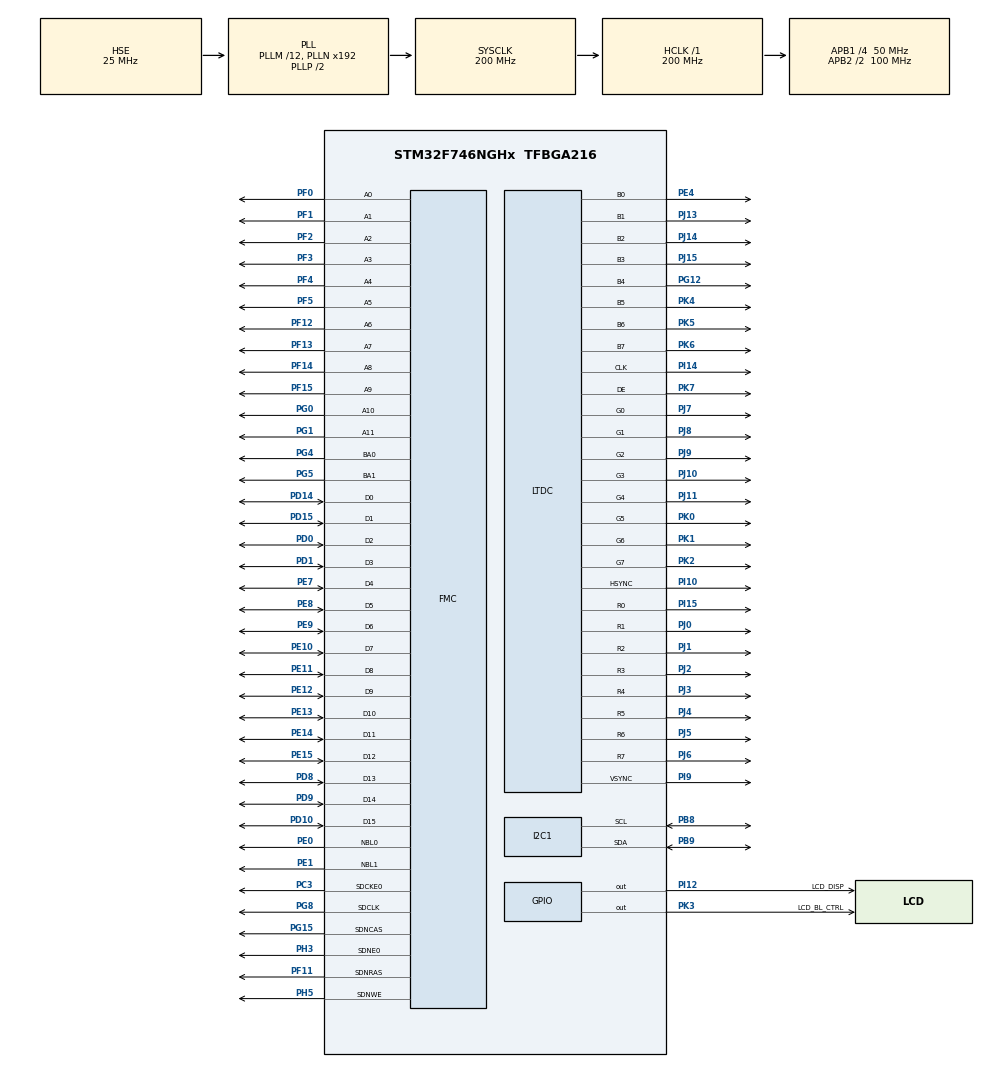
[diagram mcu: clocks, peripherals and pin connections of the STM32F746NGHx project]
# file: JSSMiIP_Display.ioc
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CORTEX_M7.CPU_DCache=Enabled
CORTEX_M7.CPU_ICache=Enabled
FMC.CASLatency1=FMC_SDRAM_CAS_LATENCY_2
FMC.ExitSelfRefreshDelay1=6
FMC.LoadToActiveDelay1=2
FMC.RCDDelay1=2
FMC.RPDelay1=2
FMC.RowCycleDelay1=6
FMC.SDClockPeriod1=FMC_SDRAM_CLOCK_PERIOD_2
FMC.SelfRefreshTime1=4
FMC.WriteRecoveryTime1=2
I2C1.Timing=0x00C0EAFF
LTDC.ActiveH=272
LTDC.ActiveW=480
LTDC.Alpha_L0=255
LTDC.Alpha_L1=255
LTDC.BlendingFactor1_L0=LTDC_BLENDING_FACTOR1_PAxCA
LTDC.BlendingFactor1_L1=LTDC_BLENDING_FACTOR1_PAxCA
LTDC.BlendingFactor2_L0=LTDC_BLENDING_FACTOR2_PAxCA
LTDC.BlendingFactor2_L1=LTDC_BLENDING_FACTOR2_PAxCA
LTDC.FBStartAdress_L0=0xC0000000
LTDC.FBStartAdress_L1=0xC0000000+0x400000
LTDC.HBP=43
LTDC.HFP=8
LTDC.HSync=1
LTDC.ImageHeight_L0=272
LTDC.ImageHeight_L1=272
LTDC.ImageWidth_L0=480
LTDC.ImageWidth_L1=480
LTDC.VBP=12
LTDC.VFP=4
LTDC.VSync=10
LTDC.WindowX1_L0=480
LTDC.WindowX1_L1=480
LTDC.WindowY1_L0=272
LTDC.WindowY1_L1=272
Mcu.Family=STM32F7
Mcu.Name=STM32F746NGHx
Mcu.Package=TFBGA216
NVIC.I2C1_ER_IRQn=true\:0\:0\:false\:false\:true\:true\:true
NVIC.I2C1_EV_IRQn=true\:0\:0\:false\:false\:true\:true\:true
NVIC.PriorityGroup=NVIC_PRIORITYGROUP_4
NVIC.TIM6_DAC_IRQn=true\:0\:0\:true\:false\:true\:true\:true
NVIC.TIM7_IRQn=true\:0\:0\:false\:false\:true\:true\:true
PA13.Mode=Serial_Wire
PA13.Signal=SYS_JTMS-SWDIO
PA14.Mode=Serial_Wire
PA14.Signal=SYS_JTCK-SWCLK
PB8.Mode=I2C
PB8.Signal=I2C1_SCL
PB9.Mode=I2C
PB9.Signal=I2C1_SDA
PC3.Mode=SdramChipSelect1_1
PC3.Signal=FMC_SDCKE0
PD0.Signal=FMC_D2_DA2
PD1.Signal=FMC_D3_DA3
PD10.Signal=FMC_D15_DA15
PD14.Signal=FMC_D0_DA0
PD15.Signal=FMC_D1_DA1
PD8.Signal=FMC_D13_DA13
PD9.Signal=FMC_D14_DA14
PE0.Signal=FMC_NBL0
PE1.Signal=FMC_NBL1
PE10.Signal=FMC_D7_DA7
PE11.Signal=FMC_D8_DA8
PE12.Signal=FMC_D9_DA9
PE13.Signal=FMC_D10_DA10
PE14.Signal=FMC_D11_DA11
PE15.Signal=FMC_D12_DA12
PE4.GPIO_Speed=GPIO_SPEED_FREQ_VERY_HIGH
PE4.Mode=RGB888
PE4.Signal=LTDC_B0
PE7.Signal=FMC_D4_DA4
PE8.Signal=FMC_D5_DA5
PE9.Signal=FMC_D6_DA6
PF0.Signal=FMC_A0
PF1.Signal=FMC_A1
PF11.Signal=FMC_SDNRAS
PF12.Signal=FMC_A6
PF13.Signal=FMC_A7
PF14.Signal=FMC_A8
PF15.Signal=FMC_A9
PF2.Signal=FMC_A2
PF3.Signal=FMC_A3
PF4.Signal=FMC_A4
PF5.Signal=FMC_A5
PG0.Signal=FMC_A10
PG1.Signal=FMC_A11
PG12.GPIO_Speed=GPIO_SPEED_FREQ_VERY_HIGH
PG12.Mode=RGB888
PG12.Signal=LTDC_B4
PG15.Signal=FMC_SDNCAS
PG4.Signal=FMC_A14_BA0
PG5.Signal=FMC_A15_BA1
PG8.Signal=FMC_SDCLK
PH0/OSC_IN.Mode=HSE-External-Oscillator
PH0/OSC_IN.Signal=RCC_OSC_IN
PH1/OSC_OUT.Mode=HSE-External-Oscillator
PH1/OSC_OUT.Signal=RCC_OSC_OUT
PH3.Mode=SdramChipSelect1_1
PH3.Signal=FMC_SDNE0
PH5.Signal=FMC_SDNWE
PI10.GPIO_Speed=GPIO_SPEED_FREQ_VERY_HIGH
PI10.Mode=RGB888
PI10.Signal=LTDC_HSYNC
PI12.GPIO_Label=LCD_DISP
PI12.PinState=GPIO_PIN_SET
PI12.Signal=GPIO_Output
PI14.GPIO_Speed=GPIO_SPEED_FREQ_VERY_HIGH
PI14.Mode=RGB888
PI14.Signal=LTDC_CLK
PI15.GPIO_Speed=GPIO_SPEED_FREQ_VERY_HIGH
PI15.Mode=RGB888
PI15.Signal=LTDC_R0
PI9.GPIO_Speed=GPIO_SPEED_FREQ_VERY_HIGH
PI9.Mode=RGB888
PI9.Signal=LTDC_VSYNC
PJ0.GPIO_Speed=GPIO_SPEED_FREQ_VERY_HIGH
PJ0.Mode=RGB888
PJ0.Signal=LTDC_R1
PJ1.GPIO_Speed=GPIO_SPEED_FREQ_VERY_HIGH
PJ1.Mode=RGB888
PJ1.Signal=LTDC_R2
PJ10.GPIO_Speed=GPIO_SPEED_FREQ_VERY_HIGH
PJ10.Mode=RGB888
PJ10.Signal=LTDC_G3
PJ11.GPIO_Speed=GPIO_SPEED_FREQ_VERY_HIGH
PJ11.Mode=RGB888
PJ11.Signal=LTDC_G4
PJ13.GPIO_Speed=GPIO_SPEED_FREQ_VERY_HIGH
PJ13.Mode=RGB888
PJ13.Signal=LTDC_B1
PJ14.GPIO_Speed=GPIO_SPEED_FREQ_VERY_HIGH
PJ14.Mode=RGB888
PJ14.Signal=LTDC_B2
PJ15.GPIO_Speed=GPIO_SPEED_FREQ_VERY_HIGH
PJ15.Mode=RGB888
PJ15.Signal=LTDC_B3
PJ2.GPIO_Speed=GPIO_SPEED_FREQ_VERY_HIGH
PJ2.Mode=RGB888
PJ2.Signal=LTDC_R3
PJ3.GPIO_Speed=GPIO_SPEED_FREQ_VERY_HIGH
PJ3.Mode=RGB888
PJ3.Signal=LTDC_R4
PJ4.GPIO_Speed=GPIO_SPEED_FREQ_VERY_HIGH
PJ4.Mode=RGB888
PJ4.Signal=LTDC_R5
PJ5.GPIO_Speed=GPIO_SPEED_FREQ_VERY_HIGH
PJ5.Mode=RGB888
PJ5.Signal=LTDC_R6
PJ6.GPIO_Speed=GPIO_SPEED_FREQ_VERY_HIGH
PJ6.Mode=RGB888
PJ6.Signal=LTDC_R7
PJ7.GPIO_Speed=GPIO_SPEED_FREQ_VERY_HIGH
PJ7.Mode=RGB888
PJ7.Signal=LTDC_G0
PJ8.GPIO_Speed=GPIO_SPEED_FREQ_VERY_HIGH
PJ8.Mode=RGB888
PJ8.Signal=LTDC_G1
PJ9.GPIO_Speed=GPIO_SPEED_FREQ_VERY_HIGH
PJ9.Mode=RGB888
PJ9.Signal=LTDC_G2
PK0.GPIO_Speed=GPIO_SPEED_FREQ_VERY_HIGH
PK0.Mode=RGB888
PK0.Signal=LTDC_G5
PK1.GPIO_Speed=GPIO_SPEED_FREQ_VERY_HIGH
PK1.Mode=RGB888
PK1.Signal=LTDC_G6
PK2.GPIO_Speed=GPIO_SPEED_FREQ_VERY_HIGH
PK2.Mode=RGB888
PK2.Signal=LTDC_G7
PK3.GPIO_Label=LCD_BL_CTRL
PK3.PinState=GPIO_PIN_SET
PK3.Signal=GPIO_Output
PK4.GPIO_Speed=GPIO_SPEED_FREQ_VERY_HIGH
PK4.Mode=RGB888
PK4.Signal=LTDC_B5
PK5.GPIO_Speed=GPIO_SPEED_FREQ_VERY_HIGH
PK5.Mode=RGB888
PK5.Signal=LTDC_B6
PK6.GPIO_Speed=GPIO_SPEED_FREQ_VERY_HIGH
PK6.Mode=RGB888
PK6.Signal=LTDC_B7
PK7.GPIO_Speed=GPIO_SPEED_FREQ_VERY_HIGH
PK7.Mode=RGB888
PK7.Signal=LTDC_DE
ProjectManager.HeapSize=0x200
ProjectManager.StackSize=0x400
ProjectManager.TargetToolchain=STM32CubeIDE
RCC.AHBFreq_Value=200000000
RCC.APB1CLKDivider=RCC_HCLK_DIV4
RCC.APB1Freq_Value=50000000
RCC.APB1TimFreq_Value=100000000
RCC.APB2CLKDivider=RCC_HCLK_DIV2
RCC.APB2Freq_Value=100000000
RCC.APB2TimFreq_Value=200000000
RCC.CortexFreq_Value=200000000
RCC.HCLKFreq_Value=200000000
RCC.HSE_VALUE=25000000
RCC.HSI_VALUE=16000000
RCC.LSE_VALUE=32768
RCC.PLLM=12
RCC.PLLSAIN=55
RCC.PLLSAIR=3
RCC.PLLSAIRDiv=RCC_PLLSAIDIVR_4
RCC.PLLSourceVirtual=RCC_PLLSOURCE_HSE
RCC.SYSCLKFreq_VALUE=200000000
RCC.SYSCLKSource=RCC_SYSCLKSOURCE_PLLCLK
RCC.USBFreq_Value=200000000
RCC.VCOOutputFreq_Value=400000000
SH.FMC_A0.0=FMC_A0,12b-sda1
SH.FMC_A1.0=FMC_A1,12b-sda1
SH.FMC_A10.0=FMC_A10,12b-sda1
SH.FMC_A11.0=FMC_A11,12b-sda1
SH.FMC_A14_BA0.0=FMC_BA0,FourSdramBanks1
SH.FMC_A15_BA1.0=FMC_BA1,FourSdramBanks1
SH.FMC_A2.0=FMC_A2,12b-sda1
SH.FMC_A3.0=FMC_A3,12b-sda1
SH.FMC_A4.0=FMC_A4,12b-sda1
SH.FMC_A5.0=FMC_A5,12b-sda1
SH.FMC_A6.0=FMC_A6,12b-sda1
SH.FMC_A7.0=FMC_A7,12b-sda1
SH.FMC_A8.0=FMC_A8,12b-sda1
SH.FMC_A9.0=FMC_A9,12b-sda1
SH.FMC_D0_DA0.0=FMC_D0,sd-16b-d1
SH.FMC_D10_DA10.0=FMC_D10,sd-16b-d1
SH.FMC_D11_DA11.0=FMC_D11,sd-16b-d1
SH.FMC_D12_DA12.0=FMC_D12,sd-16b-d1
SH.FMC_D13_DA13.0=FMC_D13,sd-16b-d1
SH.FMC_D14_DA14.0=FMC_D14,sd-16b-d1
SH.FMC_D15_DA15.0=FMC_D15,sd-16b-d1
SH.FMC_D1_DA1.0=FMC_D1,sd-16b-d1
SH.FMC_D2_DA2.0=FMC_D2,sd-16b-d1
SH.FMC_D3_DA3.0=FMC_D3,sd-16b-d1
SH.FMC_D4_DA4.0=FMC_D4,sd-16b-d1
SH.FMC_D5_DA5.0=FMC_D5,sd-16b-d1
SH.FMC_D6_DA6.0=FMC_D6,sd-16b-d1
SH.FMC_D7_DA7.0=FMC_D7,sd-16b-d1
SH.FMC_D8_DA8.0=FMC_D8,sd-16b-d1
SH.FMC_D9_DA9.0=FMC_D9,sd-16b-d1
SH.FMC_NBL0.0=FMC_NBL0,Sd2ByteEnable1
SH.FMC_NBL1.0=FMC_NBL1,Sd2ByteEnable1
SH.FMC_SDCLK.0=FMC_SDCLK,12b-sda1
SH.FMC_SDNCAS.0=FMC_SDNCAS,12b-sda1
SH.FMC_SDNRAS.0=FMC_SDNRAS,12b-sda1
SH.FMC_SDNWE.0=FMC_SDNWE,12b-sda1
TIM6.Period=999
TIM6.Prescaler=99
TIM7.Period=9999
TIM7.Prescaler=9999
VP_TIM6_VS_ClockSourceINT.Mode=Enable_Timer
VP_TIM7_VS_ClockSourceINT.Mode=Enable_Timer
board=custom

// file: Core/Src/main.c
/* USER CODE BEGIN Header */
/**
  ******************************************************************************
  * @file           : main.c
  * @brief          : Main program body
  ******************************************************************************
  * @attention
  *
  * <h2><center>&copy; Copyright (c) 2022 STMicroelectronics.
  * All rights reserved.</center></h2>
  *
  * This software component is licensed by ST under BSD 3-Clause license,
  * the "License"; You may not use this file except in compliance with the
  * License. You may obtain a copy of the License at:
  *                        opensource.org/licenses/BSD-3-Clause
  *
  ******************************************************************************
  */
/* USER CODE END Header */
#include "main.h"

/* USER CODE BEGIN Includes */
#include "app.h"
#include "AltIMU10v5/LPS25H.h"
/* USER CODE END Includes */

I2C_HandleTypeDef hi2c1;

LTDC_HandleTypeDef hltdc;

TIM_HandleTypeDef htim6;
TIM_HandleTypeDef htim7;

SDRAM_HandleTypeDef hsdram1;

void SystemClock_Config(void);
static void MX_GPIO_Init(void);
static void MX_FMC_Init(void);
static void MX_LTDC_Init(void);
static void MX_TIM6_Init(void);
static void MX_I2C1_Init(void);
static void MX_TIM7_Init(void);

int main(void)
{

  /* Enable I-Cache---------------------------------------------------------*/
  SCB_EnableICache();

  /* Enable D-Cache---------------------------------------------------------*/
  SCB_EnableDCache();

  /* MCU Configuration--------------------------------------------------------*/

  /* Reset of all peripherals, Initializes the Flash interface and the Systick. */
  HAL_Init();

  /* Configure the system clock */
  SystemClock_Config();

  /* Initialize all configured peripherals */
  MX_GPIO_Init();
  MX_FMC_Init();
  MX_LTDC_Init();
  MX_TIM6_Init();
  MX_I2C1_Init();
  MX_TIM7_Init();
  /* USER CODE BEGIN 2 */
  app_Init();
  //app_loop();
  /* USER CODE END 2 */

  /* Infinite loop */
  /* USER CODE BEGIN WHILE */
  while (1)
  {
	  app_loop();
    /* USER CODE END WHILE */

  }
}

void SystemClock_Config(void)
{
  RCC_OscInitTypeDef RCC_OscInitStruct = {0};
  RCC_ClkInitTypeDef RCC_ClkInitStruct = {0};
  RCC_PeriphCLKInitTypeDef PeriphClkInitStruct = {0};

  /** Configure the main internal regulator output voltage
  */
  __HAL_RCC_PWR_CLK_ENABLE();
  __HAL_PWR_VOLTAGESCALING_CONFIG(PWR_REGULATOR_VOLTAGE_SCALE1);
  /** Initializes the RCC Oscillators according to the specified parameters
  * in the RCC_OscInitTypeDef structure.
  */
  RCC_OscInitStruct.OscillatorType = RCC_OSCILLATORTYPE_HSE;
  RCC_OscInitStruct.HSEState = RCC_HSE_ON;
  RCC_OscInitStruct.PLL.PLLState = RCC_PLL_ON;
  RCC_OscInitStruct.PLL.PLLSource = RCC_PLLSOURCE_HSE;
  RCC_OscInitStruct.PLL.PLLM = 12;
  RCC_OscInitStruct.PLL.PLLN = 192;
  RCC_OscInitStruct.PLL.PLLP = RCC_PLLP_DIV2;
  RCC_OscInitStruct.PLL.PLLQ = 2;
  if (HAL_RCC_OscConfig(&RCC_OscInitStruct) != HAL_OK)
  {
    Error_Handler();
  }
  /** Activate the Over-Drive mode
  */
  if (HAL_PWREx_EnableOverDrive() != HAL_OK)
  {
    Error_Handler();
  }
  /** Initializes the CPU, AHB and APB buses clocks
  */
  RCC_ClkInitStruct.ClockType = RCC_CLOCKTYPE_HCLK|RCC_CLOCKTYPE_SYSCLK
                              |RCC_CLOCKTYPE_PCLK1|RCC_CLOCKTYPE_PCLK2;
  RCC_ClkInitStruct.SYSCLKSource = RCC_SYSCLKSOURCE_PLLCLK;
  RCC_ClkInitStruct.AHBCLKDivider = RCC_SYSCLK_DIV1;
  RCC_ClkInitStruct.APB1CLKDivider = RCC_HCLK_DIV4;
  RCC_ClkInitStruct.APB2CLKDivider = RCC_HCLK_DIV2;

  if (HAL_RCC_ClockConfig(&RCC_ClkInitStruct, FLASH_LATENCY_6) != HAL_OK)
  {
    Error_Handler();
  }
  PeriphClkInitStruct.PeriphClockSelection = RCC_PERIPHCLK_LTDC|RCC_PERIPHCLK_I2C1;
  PeriphClkInitStruct.PLLSAI.PLLSAIN = 55;
  PeriphClkInitStruct.PLLSAI.PLLSAIR = 3;
  PeriphClkInitStruct.PLLSAI.PLLSAIQ = 2;
  PeriphClkInitStruct.PLLSAI.PLLSAIP = RCC_PLLSAIP_DIV2;
  PeriphClkInitStruct.PLLSAIDivQ = 1;
  PeriphClkInitStruct.PLLSAIDivR = RCC_PLLSAIDIVR_4;
  PeriphClkInitStruct.I2c1ClockSelection = RCC_I2C1CLKSOURCE_PCLK1;
  if (HAL_RCCEx_PeriphCLKConfig(&PeriphClkInitStruct) != HAL_OK)
  {
    Error_Handler();
  }
}

static void MX_I2C1_Init(void)
{

  hi2c1.Instance = I2C1;
  hi2c1.Init.Timing = 0x00C0EAFF;
  hi2c1.Init.OwnAddress1 = 0;
  hi2c1.Init.AddressingMode = I2C_ADDRESSINGMODE_7BIT;
  hi2c1.Init.DualAddressMode = I2C_DUALADDRESS_DISABLE;
  hi2c1.Init.OwnAddress2 = 0;
  hi2c1.Init.OwnAddress2Masks = I2C_OA2_NOMASK;
  hi2c1.Init.GeneralCallMode = I2C_GENERALCALL_DISABLE;
  hi2c1.Init.NoStretchMode = I2C_NOSTRETCH_DISABLE;
  if (HAL_I2C_Init(&hi2c1) != HAL_OK)
  {
    Error_Handler();
  }
  /** Configure Analogue filter
  */
  if (HAL_I2CEx_ConfigAnalogFilter(&hi2c1, I2C_ANALOGFILTER_ENABLE) != HAL_OK)
  {
    Error_Handler();
  }
  /** Configure Digital filter
  */
  if (HAL_I2CEx_ConfigDigitalFilter(&hi2c1, 0) != HAL_OK)
  {
    Error_Handler();
  }

}

static void MX_LTDC_Init(void)
{

  LTDC_LayerCfgTypeDef pLayerCfg = {0};
  LTDC_LayerCfgTypeDef pLayerCfg1 = {0};

  hltdc.Instance = LTDC;
  hltdc.Init.HSPolarity = LTDC_HSPOLARITY_AL;
  hltdc.Init.VSPolarity = LTDC_VSPOLARITY_AL;
  hltdc.Init.DEPolarity = LTDC_DEPOLARITY_AL;
  hltdc.Init.PCPolarity = LTDC_PCPOLARITY_IPC;
  hltdc.Init.HorizontalSync = 0;
  hltdc.Init.VerticalSync = 9;
  hltdc.Init.AccumulatedHBP = 43;
  hltdc.Init.AccumulatedVBP = 21;
  hltdc.Init.AccumulatedActiveW = 523;
  hltdc.Init.AccumulatedActiveH = 293;
  hltdc.Init.TotalWidth = 531;
  hltdc.Init.TotalHeigh = 297;
  hltdc.Init.Backcolor.Blue = 0;
  hltdc.Init.Backcolor.Green = 0;
  hltdc.Init.Backcolor.Red = 0;
  if (HAL_LTDC_Init(&hltdc) != HAL_OK)
  {
    Error_Handler();
  }
  pLayerCfg.WindowX0 = 0;
  pLayerCfg.WindowX1 = 480;
  pLayerCfg.WindowY0 = 0;
  pLayerCfg.WindowY1 = 272;
  pLayerCfg.PixelFormat = LTDC_PIXEL_FORMAT_ARGB8888;
  pLayerCfg.Alpha = 255;
  pLayerCfg.Alpha0 = 0;
  pLayerCfg.BlendingFactor1 = LTDC_BLENDING_FACTOR1_PAxCA;
  pLayerCfg.BlendingFactor2 = LTDC_BLENDING_FACTOR2_PAxCA;
  pLayerCfg.FBStartAdress = 0xC0000000;
  pLayerCfg.ImageWidth = 480;
  pLayerCfg.ImageHeight = 272;
  pLayerCfg.Backcolor.Blue = 0;
  pLayerCfg.Backcolor.Green = 0;
  pLayerCfg.Backcolor.Red = 0;
  if (HAL_LTDC_ConfigLayer(&hltdc, &pLayerCfg, 0) != HAL_OK)
  {
    Error_Handler();
  }
  pLayerCfg1.WindowX0 = 0;
  pLayerCfg1.WindowX1 = 480;
  pLayerCfg1.WindowY0 = 0;
  pLayerCfg1.WindowY1 = 272;
  pLayerCfg1.PixelFormat = LTDC_PIXEL_FORMAT_ARGB8888;
  pLayerCfg1.Alpha = 255;
  pLayerCfg1.Alpha0 = 0;
  pLayerCfg1.BlendingFactor1 = LTDC_BLENDING_FACTOR1_PAxCA;
  pLayerCfg1.BlendingFactor2 = LTDC_BLENDING_FACTOR2_PAxCA;
  pLayerCfg1.FBStartAdress = 0xC0000000+0x400000;
  pLayerCfg1.ImageWidth = 480;
  pLayerCfg1.ImageHeight = 272;
  pLayerCfg1.Backcolor.Blue = 0;
  pLayerCfg1.Backcolor.Green = 0;
  pLayerCfg1.Backcolor.Red = 0;
  if (HAL_LTDC_ConfigLayer(&hltdc, &pLayerCfg1, 1) != HAL_OK)
  {
    Error_Handler();
  }

}

static void MX_TIM6_Init(void)
{

  TIM_MasterConfigTypeDef sMasterConfig = {0};

  htim6.Instance = TIM6;
  htim6.Init.Prescaler = 99;
  htim6.Init.CounterMode = TIM_COUNTERMODE_UP;
  htim6.Init.Period = 999;
  htim6.Init.AutoReloadPreload = TIM_AUTORELOAD_PRELOAD_DISABLE;
  if (HAL_TIM_Base_Init(&htim6) != HAL_OK)
  {
    Error_Handler();
  }
  sMasterConfig.MasterOutputTrigger = TIM_TRGO_RESET;
  sMasterConfig.MasterSlaveMode = TIM_MASTERSLAVEMODE_DISABLE;
  if (HAL_TIMEx_MasterConfigSynchronization(&htim6, &sMasterConfig) != HAL_OK)
  {
    Error_Handler();
  }

}

static void MX_TIM7_Init(void)
{

  TIM_MasterConfigTypeDef sMasterConfig = {0};

  htim7.Instance = TIM7;
  htim7.Init.Prescaler = 9999;
  htim7.Init.CounterMode = TIM_COUNTERMODE_UP;
  htim7.Init.Period = 9999;
  htim7.Init.AutoReloadPreload = TIM_AUTORELOAD_PRELOAD_DISABLE;
  if (HAL_TIM_Base_Init(&htim7) != HAL_OK)
  {
    Error_Handler();
  }
  sMasterConfig.MasterOutputTrigger = TIM_TRGO_RESET;
  sMasterConfig.MasterSlaveMode = TIM_MASTERSLAVEMODE_DISABLE;
  if (HAL_TIMEx_MasterConfigSynchronization(&htim7, &sMasterConfig) != HAL_OK)
  {
    Error_Handler();
  }

}

/* FMC initialization function */
static void MX_FMC_Init(void)
{

  FMC_SDRAM_TimingTypeDef SdramTiming = {0};

  /** Perform the SDRAM1 memory initialization sequence
  */
  hsdram1.Instance = FMC_SDRAM_DEVICE;
  /* hsdram1.Init */
  hsdram1.Init.SDBank = FMC_SDRAM_BANK1;
  hsdram1.Init.ColumnBitsNumber = FMC_SDRAM_COLUMN_BITS_NUM_8;
  hsdram1.Init.RowBitsNumber = FMC_SDRAM_ROW_BITS_NUM_12;
  hsdram1.Init.MemoryDataWidth = FMC_SDRAM_MEM_BUS_WIDTH_16;
  hsdram1.Init.InternalBankNumber = FMC_SDRAM_INTERN_BANKS_NUM_4;
  hsdram1.Init.CASLatency = FMC_SDRAM_CAS_LATENCY_2;
  hsdram1.Init.WriteProtection = FMC_SDRAM_WRITE_PROTECTION_DISABLE;
  hsdram1.Init.SDClockPeriod = FMC_SDRAM_CLOCK_PERIOD_2;
  hsdram1.Init.ReadBurst = FMC_SDRAM_RBURST_DISABLE;
  hsdram1.Init.ReadPipeDelay = FMC_SDRAM_RPIPE_DELAY_0;
  /* SdramTiming */
  SdramTiming.LoadToActiveDelay = 2;
  SdramTiming.ExitSelfRefreshDelay = 6;
  SdramTiming.SelfRefreshTime = 4;
  SdramTiming.RowCycleDelay = 6;
  SdramTiming.WriteRecoveryTime = 2;
  SdramTiming.RPDelay = 2;
  SdramTiming.RCDDelay = 2;

  if (HAL_SDRAM_Init(&hsdram1, &SdramTiming) != HAL_OK)
  {
    Error_Handler( );
  }

}

static void MX_GPIO_Init(void)
{
  GPIO_InitTypeDef GPIO_InitStruct = {0};

  /* GPIO Ports Clock Enable */
  __HAL_RCC_GPIOE_CLK_ENABLE();
  __HAL_RCC_GPIOB_CLK_ENABLE();
  __HAL_RCC_GPIOA_CLK_ENABLE();
  __HAL_RCC_GPIOG_CLK_ENABLE();
  __HAL_RCC_GPIOJ_CLK_ENABLE();
  __HAL_RCC_GPIOD_CLK_ENABLE();
  __HAL_RCC_GPIOK_CLK_ENABLE();
  __HAL_RCC_GPIOF_CLK_ENABLE();
  __HAL_RCC_GPIOI_CLK_ENABLE();
  __HAL_RCC_GPIOH_CLK_ENABLE();
  __HAL_RCC_GPIOC_CLK_ENABLE();

  /*Configure GPIO pin Output Level */
  HAL_GPIO_WritePin(LCD_BL_CTRL_GPIO_Port, LCD_BL_CTRL_Pin, GPIO_PIN_SET);

  /*Configure GPIO pin Output Level */
  HAL_GPIO_WritePin(LCD_DISP_GPIO_Port, LCD_DISP_Pin, GPIO_PIN_SET);

  /*Configure GPIO pin : LCD_BL_CTRL_Pin */
  GPIO_InitStruct.Pin = LCD_BL_CTRL_Pin;
  GPIO_InitStruct.Mode = GPIO_MODE_OUTPUT_PP;
  GPIO_InitStruct.Pull = GPIO_NOPULL;
  GPIO_InitStruct.Speed = GPIO_SPEED_FREQ_LOW;
  HAL_GPIO_Init(LCD_BL_CTRL_GPIO_Port, &GPIO_InitStruct);

  /*Configure GPIO pin : LCD_DISP_Pin */
  GPIO_InitStruct.Pin = LCD_DISP_Pin;
  GPIO_InitStruct.Mode = GPIO_MODE_OUTPUT_PP;
  GPIO_InitStruct.Pull = GPIO_NOPULL;
  GPIO_InitStruct.Speed = GPIO_SPEED_FREQ_LOW;
  HAL_GPIO_Init(LCD_DISP_GPIO_Port, &GPIO_InitStruct);

}

void Error_Handler(void)
{
  __disable_irq();
  while (1)
  {
  }
}

/************************ (C) COPYRIGHT STMicroelectronics *****END OF FILE****/
